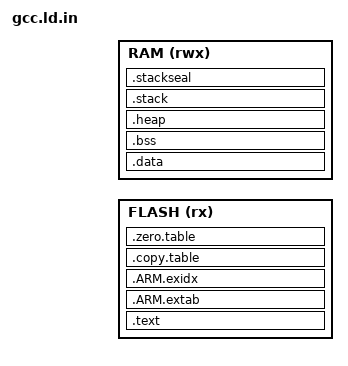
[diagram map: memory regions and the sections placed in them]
/*
 * Copyright (c) 2009-2022 Arm Limited. All rights reserved.
 *
 * SPDX-License-Identifier: Apache-2.0
 *
 * Licensed under the Apache License, Version 2.0 (the License); you may
 * not use this file except in compliance with the License.
 * You may obtain a copy of the License at
 *
 * www.apache.org/licenses/LICENSE-2.0
 *
 * Unless required by applicable law or agreed to in writing, software
 * distributed under the License is distributed on an AS IS BASIS, WITHOUT
 * WARRANTIES OR CONDITIONS OF ANY KIND, either express or implied.
 * See the License for the specific language governing permissions and
 * limitations under the License.
 */

/*
 * Note: This file is based on Device/ARM/ARMCM55/Source/GCC/gcc_arm.ld from
 * the git tag 5.8.0 of the CMSIS_5 repository.
 */

/*
 *-------- <<< Use Configuration Wizard in Context Menu >>> -------------------
 */

/*---------------------- Flash Configuration ----------------------------------
  <h> Flash Configuration
    <o0> Flash Base Address <0x0-0xFFFFFFFF:8>
    <o1> Flash Size (in Bytes) <0x0-0xFFFFFFFF:8>
  </h>
  -----------------------------------------------------------------------------*/
__ROM_BASE = @ROM_BASE@;
__ROM_SIZE = @ROM_SIZE@;

/*--------------------- Embedded RAM Configuration ----------------------------
  <h> RAM Configuration
    <o0> RAM Base Address    <0x0-0xFFFFFFFF:8>
    <o1> RAM Size (in Bytes) <0x0-0xFFFFFFFF:8>
  </h>
 -----------------------------------------------------------------------------*/
__RAM_BASE = @RAM_BASE@;
__RAM_SIZE = @RAM_SIZE@;

/*--------------------- Stack / Heap Configuration ----------------------------
  <h> Stack / Heap Configuration
    <o0> Stack Size (in Bytes) <0x0-0xFFFFFFFF:8>
    <o1> Heap Size (in Bytes) <0x0-0xFFFFFFFF:8>
  </h>
  -----------------------------------------------------------------------------*/
__STACK_SIZE = @STACK_SIZE@;
__HEAP_SIZE  = @HEAP_SIZE@;

/*
 *-------------------- <<< end of configuration section >>> -------------------
 */

/* ARMv8-M stack sealing:
   to use ARMv8-M stack sealing set __STACKSEAL_SIZE to 8 otherwise keep 0
 */
__STACKSEAL_SIZE = 0;


MEMORY
{
  FLASH (rx)  : ORIGIN = __ROM_BASE, LENGTH = __ROM_SIZE
  RAM   (rwx) : ORIGIN = __RAM_BASE, LENGTH = __RAM_SIZE
}

/* Linker script to place sections and symbol values.
 * It references following symbols, which must be defined in code:
 *   Reset_Handler : Entry of reset handler
 *
 * It defines following symbols, which code can use without definition:
 *   __exidx_start
 *   __exidx_end
 *   __copy_table_start__
 *   __copy_table_end__
 *   __zero_table_start__
 *   __zero_table_end__
 *   __etext
 *   __data_start__
 *   __preinit_array_start
 *   __preinit_array_end
 *   __init_array_start
 *   __init_array_end
 *   __fini_array_start
 *   __fini_array_end
 *   __data_end__
 *   __bss_start__
 *   __bss_end__
 *   __end__
 *   end
 *   __HeapLimit
 *   __StackLimit
 *   __StackTop
 *   __stack
 *   __StackSeal      (only if ARMv8-M stack sealing is used)
 */
ENTRY(Reset_Handler)

SECTIONS
{
  .text :
  {
    _vectors = .;
    KEEP(*(.vectors))
    *(.text*)

    KEEP(*(.init))
    KEEP(*(.fini))

    /* .ctors */
    *crtbegin.o(.ctors)
    *crtbegin?.o(.ctors)
    *(EXCLUDE_FILE(*crtend?.o *crtend.o) .ctors)
    *(SORT(.ctors.*))
    *(.ctors)

    /* .dtors */
    *crtbegin.o(.dtors)
    *crtbegin?.o(.dtors)
    *(EXCLUDE_FILE(*crtend?.o *crtend.o) .dtors)
    *(SORT(.dtors.*))
    *(.dtors)

    *(.rodata*)

    KEEP(*(.eh_frame*))
  } > FLASH

  .ARM.extab :
  {
    *(.ARM.extab* .gnu.linkonce.armextab.*)
  } > FLASH

  __exidx_start = .;
  .ARM.exidx :
  {
    *(.ARM.exidx* .gnu.linkonce.armexidx.*)
  } > FLASH
  __exidx_end = .;

  .copy.table :
  {
    . = ALIGN(4);
    __copy_table_start__ = .;

    LONG (__etext)
    LONG (__data_start__)
    LONG ((__data_end__ - __data_start__) / 4)

    __copy_table_end__ = .;
  } > FLASH

  .zero.table :
  {
    . = ALIGN(4);
    __zero_table_start__ = .;
    __zero_table_end__ = .;
  } > FLASH

  /**
   * Location counter can end up 2byte aligned with narrow Thumb code but
   * __etext is assumed by startup code to be the LMA of a section in RAM
   * which must be 4byte aligned
   */
  __etext = ALIGN (4);

  .data : AT (__etext)
  {
    __data_start__ = .;
    *(vtable)
    *(.data)
    *(.data.*)

    . = ALIGN(4);
    /* preinit data */
    PROVIDE_HIDDEN (__preinit_array_start = .);
    KEEP(*(.preinit_array))
    PROVIDE_HIDDEN (__preinit_array_end = .);

    . = ALIGN(4);
    /* init data */
    PROVIDE_HIDDEN (__init_array_start = .);
    KEEP(*(SORT(.init_array.*)))
    KEEP(*(.init_array))
    PROVIDE_HIDDEN (__init_array_end = .);

    . = ALIGN(4);
    /* finit data */
    PROVIDE_HIDDEN (__fini_array_start = .);
    KEEP(*(SORT(.fini_array.*)))
    KEEP(*(.fini_array))
    PROVIDE_HIDDEN (__fini_array_end = .);

    KEEP(*(.jcr*))
    . = ALIGN(4);
    /* All data end */
    __data_end__ = .;

  } > RAM

  .bss :
  {
    . = ALIGN(4);
    __bss_start__ = .;
    *(.bss)
    *(.bss.*)
    *(COMMON)
    . = ALIGN(4);
    __bss_end__ = .;
  } > RAM AT > RAM

  .heap (COPY) :
  {
    . = ALIGN(8);
    __end__ = .;
    PROVIDE(end = .);
    . = . + __HEAP_SIZE;
    . = ALIGN(8);
    __HeapLimit = .;
  } > RAM
  PROVIDE(__RAM_segment_used_end__ = __HeapLimit);

  .stack (ORIGIN(RAM) + LENGTH(RAM) - __STACK_SIZE - __STACKSEAL_SIZE) (COPY) :
  {
    . = ALIGN(8);
    __StackLimit = .;
    . = . + __STACK_SIZE;
    . = ALIGN(8);
    __StackTop = .;
  } > RAM
  PROVIDE(__stack = __StackTop);

  /* ARMv8-M stack sealing: */
  .stackseal (ORIGIN(RAM) + LENGTH(RAM) - __STACKSEAL_SIZE) (COPY) :
  {
    . = ALIGN(8);
    __StackSeal = .;
    . = . + 8;
    . = ALIGN(8);
  } > RAM

  /* Check if data + heap + stack exceeds RAM limit */
  ASSERT(__StackLimit >= __HeapLimit, "region RAM overflowed with stack")
}
